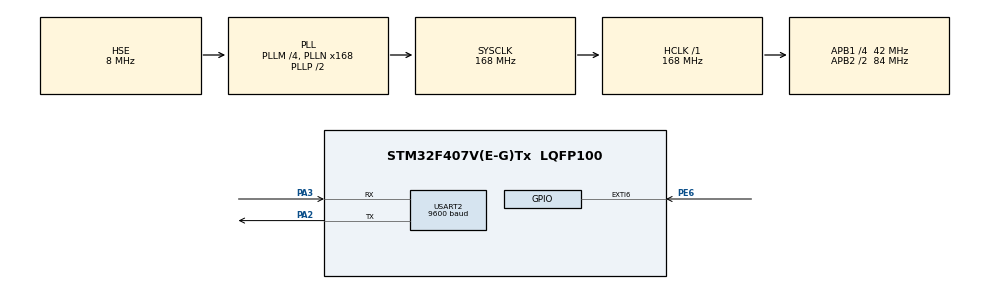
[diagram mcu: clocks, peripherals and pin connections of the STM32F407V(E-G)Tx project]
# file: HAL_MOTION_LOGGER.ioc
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Mcu.Family=STM32F4
Mcu.Name=STM32F407V(E-G)Tx
Mcu.Package=LQFP100
NVIC.EXTI9_5_IRQn=true\:1\:0\:true\:false\:true\:true\:true\:true
NVIC.PriorityGroup=NVIC_PRIORITYGROUP_4
NVIC.USART2_IRQn=true\:0\:0\:false\:false\:true\:true\:true\:true
PA2.Mode=Asynchronous
PA2.Signal=USART2_TX
PA3.Mode=Asynchronous
PA3.Signal=USART2_RX
PE6.Signal=GPXTI6
PH0-OSC_IN.Mode=HSE-External-Oscillator
PH0-OSC_IN.Signal=RCC_OSC_IN
PH1-OSC_OUT.Mode=HSE-External-Oscillator
PH1-OSC_OUT.Signal=RCC_OSC_OUT
ProjectManager.HeapSize=0x200
ProjectManager.StackSize=0x400
ProjectManager.TargetToolchain=STM32CubeIDE
RCC.48MHZClocksFreq_Value=84000000
RCC.AHBFreq_Value=168000000
RCC.APB1CLKDivider=RCC_HCLK_DIV4
RCC.APB1Freq_Value=42000000
RCC.APB1TimFreq_Value=84000000
RCC.APB2CLKDivider=RCC_HCLK_DIV2
RCC.APB2Freq_Value=84000000
RCC.APB2TimFreq_Value=168000000
RCC.CortexFreq_Value=168000000
RCC.HCLKFreq_Value=168000000
RCC.HSE_VALUE=8000000
RCC.HSI_VALUE=16000000
RCC.LSE_VALUE=32768
RCC.PLLM=4
RCC.PLLN=168
RCC.PLLSourceVirtual=RCC_PLLSOURCE_HSE
RCC.RCC_RTC_Clock_SourceVirtual=RCC_RTCCLKSOURCE_HSE_DIV20
RCC.RCC_RTC_Clock_Source_FROM_HSE=RCC_RTCCLKSOURCE_HSE_DIV20
RCC.SYSCLKFreq_VALUE=168000000
RCC.SYSCLKSource=RCC_SYSCLKSOURCE_PLLCLK
RCC.VCOOutputFreq_Value=336000000
RTC.AsynchPrediv=99
RTC.Date=28
RTC.Format=RTC_FORMAT_BIN
RTC.Hours=20
RTC.Minutes=39
RTC.SynchPrediv=3999
RTC.Year=24
USART2.BaudRate=9600
USART2.VirtualMode=VM_ASYNC
VP_RTC_VS_RTC_Activate.Mode=RTC_Enabled
VP_RTC_VS_RTC_Calendar.Mode=RTC_Calendar
board=custom

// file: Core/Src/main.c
/* USER CODE BEGIN Header */
/**
  ******************************************************************************
  * @file           : main.c
  * @brief          : Main program body
  ******************************************************************************
  * @attention
  *
  * Copyright (c) 2024 STMicroelectronics.
  * All rights reserved.
  *
  * This software is licensed under terms that can be found in the LICENSE file
  * in the root directory of this software component.
  * If no LICENSE file comes with this software, it is provided AS-IS.
  *
  ******************************************************************************
  */
/* USER CODE END Header */
#include "main.h"

/* USER CODE BEGIN Includes */
#include <stdio.h>
/* USER CODE END Includes */

RTC_HandleTypeDef hrtc;

UART_HandleTypeDef huart2;

void SystemClock_Config(void);
static void MX_GPIO_Init(void);
static void MX_RTC_Init(void);
static void MX_USART2_UART_Init(void);

/* USER CODE BEGIN 0 */
uint32_t address=0x08004000; //flash memory sector 1 address
uint8_t calendar[6]; // array for time & date for motion log
uint8_t usart_data; //usart received data
int count;
char str[55]=" 1: Display Motion Log Records \n 2: Erase Records ", log_data[20]={'\0'}; // log data array

//flash write function
void flash_write(uint32_t MyAddress, uint8_t MyData )
{
	HAL_FLASH_Unlock(); //unlock flash
	HAL_FLASH_Program(FLASH_TYPEPROGRAM_BYTE, MyAddress, MyData); //write the data to the given address
	HAL_FLASH_Lock(); //lock the flash
}

//flash read function
uint8_t flash_read(uint32_t MyAddress)
{
	uint8_t MyData;
	MyData=*(uint32_t*)MyAddress;
	return MyData;
}

void get_rtc_time()
{
	RTC_TimeTypeDef sTime={0}; //RTC structure for time
	HAL_RTC_GetTime(&hrtc, &sTime, RTC_FORMAT_BIN); //get time
	calendar[5]=sTime.Seconds;
	calendar[4]=sTime.Minutes;
	calendar[3]=sTime.Hours;
}
void get_rtc_date()
{
	RTC_DateTypeDef sDate={0}; //RTC structure for date
	HAL_RTC_GetDate(&hrtc, &sDate, RTC_FORMAT_BIN); //get date
	calendar[2]=sDate.Date;
	calendar[1]=sDate.Month;
	calendar[0]=sDate.Year;
}
//GPIO PE6 Interrupt
void EXTI9_5_IRQHandler(void)
{
  /* USER CODE BEGIN EXTI9_5_IRQn 0 */

  /* USER CODE END EXTI9_5_IRQn 0 */
  HAL_GPIO_EXTI_IRQHandler(GPIO_PIN_6);
  /* USER CODE BEGIN EXTI9_5_IRQn 1 */
get_rtc_time();
get_rtc_date();
for(int j=0; j<6; j++) //writes time and date into flash memory
{
	uint8_t MyCalendar=calendar[j];
	flash_write(address, MyCalendar);
	address++;
}

  /* USER CODE END EXTI9_5_IRQn 1 */
}

//usart interrupt
void HAL_UART_RxCpltCallback(UART_HandleTypeDef *huart)
{

	if(usart_data=='\r')
	{

	}
	else if(usart_data=='\n')
	{

	}
	else
	{
		count=usart_data-'0';
		switch(count)
		{
		case 1:
			uint32_t address_l=0x08004000;
			uint8_t data_l=flash_read(address_l);
			while(data_l != 0xFF)
			{
				for(int i=0; i<18;i+=3)
				{
				    log_data[i]=(char)((data_l / 10) + '0');   // tens digit to char
				    log_data[i+1]=(char)((data_l % 10) + '0'); // units digit to char
				    address_l++;
				    data_l=flash_read(address_l);
				}
				log_data[2] = '.';
				log_data[5] = '.';
				log_data[8] = '-';
				log_data[11] = ':';
				log_data[14] = ':';
				log_data[17] = '\n';
				HAL_UART_Transmit(&huart2, (uint8_t*)log_data, 20, 100);

			}
			break;

		case 2:
			HAL_FLASH_Unlock(); //unlock flash
			FLASH_Erase_Sector(FLASH_SECTOR_1, FLASH_VOLTAGE_RANGE_3);// erase the flash before use
			while(__HAL_FLASH_GET_FLAG(FLASH_FLAG_BSY));
			while(!__HAL_FLASH_GET_FLAG(FLASH_FLAG_EOP));
			HAL_FLASH_Lock(); //lock the flash
			break;
		}

	}
	HAL_UART_Receive_IT(&huart2, &usart_data, 1);

}
/* USER CODE END 0 */

int main(void)
{

  /* MCU Configuration--------------------------------------------------------*/

  /* Reset of all peripherals, Initializes the Flash interface and the Systick. */
  HAL_Init();

  /* Configure the system clock */
  SystemClock_Config();

  /* Initialize all configured peripherals */
  MX_GPIO_Init();
  MX_RTC_Init();
  MX_USART2_UART_Init();
  /* USER CODE BEGIN 2 */
  HAL_NVIC_EnableIRQ(USART2_IRQn);
  HAL_NVIC_SetPriority(USART2_IRQn, 0, 0);
  HAL_UART_Receive_IT(&huart2, &usart_data, 1);
  HAL_UART_Transmit(&huart2, (uint8_t*)str, 55, 100);
  HAL_FLASH_Unlock(); //unlock flash
  FLASH_Erase_Sector(FLASH_SECTOR_1, FLASH_VOLTAGE_RANGE_3);// erase the flash before use
  while(__HAL_FLASH_GET_FLAG(FLASH_FLAG_BSY));
  while(!__HAL_FLASH_GET_FLAG(FLASH_FLAG_EOP));
  HAL_FLASH_Lock(); //lock the flash

  /* USER CODE END 2 */

  /* Infinite loop */
  while (1)
  {

  }
}

void SystemClock_Config(void)
{
  RCC_OscInitTypeDef RCC_OscInitStruct = {0};
  RCC_ClkInitTypeDef RCC_ClkInitStruct = {0};

  /** Configure the main internal regulator output voltage
  */
  __HAL_RCC_PWR_CLK_ENABLE();
  __HAL_PWR_VOLTAGESCALING_CONFIG(PWR_REGULATOR_VOLTAGE_SCALE1);

  /** Initializes the RCC Oscillators according to the specified parameters
  * in the RCC_OscInitTypeDef structure.
  */
  RCC_OscInitStruct.OscillatorType = RCC_OSCILLATORTYPE_HSE;
  RCC_OscInitStruct.HSEState = RCC_HSE_ON;
  RCC_OscInitStruct.PLL.PLLState = RCC_PLL_ON;
  RCC_OscInitStruct.PLL.PLLSource = RCC_PLLSOURCE_HSE;
  RCC_OscInitStruct.PLL.PLLM = 4;
  RCC_OscInitStruct.PLL.PLLN = 168;
  RCC_OscInitStruct.PLL.PLLP = RCC_PLLP_DIV2;
  RCC_OscInitStruct.PLL.PLLQ = 4;
  if (HAL_RCC_OscConfig(&RCC_OscInitStruct) != HAL_OK)
  {
    Error_Handler();
  }

  /** Initializes the CPU, AHB and APB buses clocks
  */
  RCC_ClkInitStruct.ClockType = RCC_CLOCKTYPE_HCLK|RCC_CLOCKTYPE_SYSCLK
                              |RCC_CLOCKTYPE_PCLK1|RCC_CLOCKTYPE_PCLK2;
  RCC_ClkInitStruct.SYSCLKSource = RCC_SYSCLKSOURCE_PLLCLK;
  RCC_ClkInitStruct.AHBCLKDivider = RCC_SYSCLK_DIV1;
  RCC_ClkInitStruct.APB1CLKDivider = RCC_HCLK_DIV4;
  RCC_ClkInitStruct.APB2CLKDivider = RCC_HCLK_DIV2;

  if (HAL_RCC_ClockConfig(&RCC_ClkInitStruct, FLASH_LATENCY_5) != HAL_OK)
  {
    Error_Handler();
  }
}

static void MX_RTC_Init(void)
{

  RTC_TimeTypeDef sTime = {0};
  RTC_DateTypeDef sDate = {0};

  /** Initialize RTC Only
  */
  hrtc.Instance = RTC;
  hrtc.Init.HourFormat = RTC_HOURFORMAT_24;
  hrtc.Init.AsynchPrediv = 99;
  hrtc.Init.SynchPrediv = 3999;
  hrtc.Init.OutPut = RTC_OUTPUT_DISABLE;
  hrtc.Init.OutPutPolarity = RTC_OUTPUT_POLARITY_HIGH;
  hrtc.Init.OutPutType = RTC_OUTPUT_TYPE_OPENDRAIN;
  if (HAL_RTC_Init(&hrtc) != HAL_OK)
  {
    Error_Handler();
  }

  /** Initialize RTC and set the Time and Date
  */
  sTime.Hours = 20;
  sTime.Minutes = 39;
  sTime.Seconds = 0;
  sTime.DayLightSaving = RTC_DAYLIGHTSAVING_NONE;
  sTime.StoreOperation = RTC_STOREOPERATION_RESET;
  if (HAL_RTC_SetTime(&hrtc, &sTime, RTC_FORMAT_BIN) != HAL_OK)
  {
    Error_Handler();
  }
  sDate.WeekDay = RTC_WEEKDAY_MONDAY;
  sDate.Month = RTC_MONTH_JANUARY;
  sDate.Date = 28;
  sDate.Year = 24;

  if (HAL_RTC_SetDate(&hrtc, &sDate, RTC_FORMAT_BIN) != HAL_OK)
  {
    Error_Handler();
  }

}

static void MX_USART2_UART_Init(void)
{

  huart2.Instance = USART2;
  huart2.Init.BaudRate = 9600;
  huart2.Init.WordLength = UART_WORDLENGTH_8B;
  huart2.Init.StopBits = UART_STOPBITS_1;
  huart2.Init.Parity = UART_PARITY_NONE;
  huart2.Init.Mode = UART_MODE_TX_RX;
  huart2.Init.HwFlowCtl = UART_HWCONTROL_NONE;
  huart2.Init.OverSampling = UART_OVERSAMPLING_16;
  if (HAL_UART_Init(&huart2) != HAL_OK)
  {
    Error_Handler();
  }

}

static void MX_GPIO_Init(void)
{
  GPIO_InitTypeDef GPIO_InitStruct = {0};

  /* GPIO Ports Clock Enable */
  __HAL_RCC_GPIOE_CLK_ENABLE();
  __HAL_RCC_GPIOH_CLK_ENABLE();
  __HAL_RCC_GPIOA_CLK_ENABLE();

  /*Configure GPIO pin : PE6 */
  GPIO_InitStruct.Pin = GPIO_PIN_6;
  GPIO_InitStruct.Mode = GPIO_MODE_IT_RISING;
  GPIO_InitStruct.Pull = GPIO_NOPULL;
  HAL_GPIO_Init(GPIOE, &GPIO_InitStruct);

  /* EXTI interrupt init*/
  HAL_NVIC_SetPriority(EXTI9_5_IRQn, 1, 0);
  HAL_NVIC_EnableIRQ(EXTI9_5_IRQn);

}

void Error_Handler(void)
{
  __disable_irq();
  while (1)
  {
  }
}
